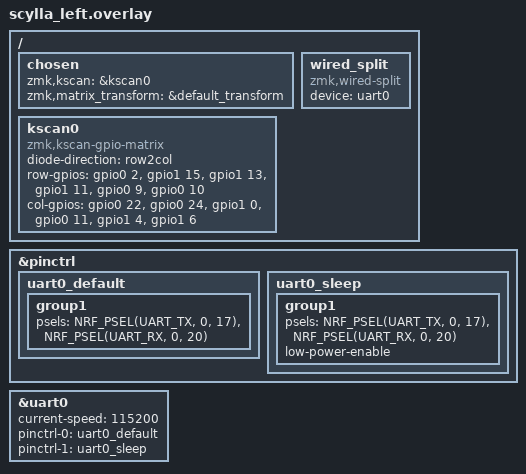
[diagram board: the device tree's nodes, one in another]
#include "scylla.dtsi"

#include <dt-bindings/gpio/gpio.h>
#include <dt-bindings/pinctrl/nrf-pinctrl.h>

/ {
    chosen {
        zmk,kscan = &kscan0;
        zmk,matrix_transform = &default_transform;
    };

    /* Wired split instance (UART) */
    wired_split: wired_split {
        compatible = "zmk,wired-split";
        device = <&uart0>;
    };

    kscan0: kscan0 {
        compatible = "zmk,kscan-gpio-matrix";
        diode-direction = "row2col";

        /* rows */
        row-gpios = <
            &gpio0 2   (GPIO_ACTIVE_HIGH | GPIO_PULL_DOWN)  /* P0.02 */
            &gpio1 15  (GPIO_ACTIVE_HIGH | GPIO_PULL_DOWN)  /* P1.15 */
            &gpio1 13  (GPIO_ACTIVE_HIGH | GPIO_PULL_DOWN)  /* P1.13 */
            &gpio1 11  (GPIO_ACTIVE_HIGH | GPIO_PULL_DOWN)  /* P1.11 */
            &gpio0 9   (GPIO_ACTIVE_HIGH | GPIO_PULL_DOWN)  /* P0.09 thumb row */
            &gpio0 10  (GPIO_ACTIVE_HIGH | GPIO_PULL_DOWN)  /* P0.10 dummy row */
        >;

        /* cols */
        col-gpios = <
            &gpio0 22 (GPIO_ACTIVE_HIGH | GPIO_PULL_DOWN) /* P0.22 */
            &gpio0 24 (GPIO_ACTIVE_HIGH | GPIO_PULL_DOWN) /* P0.24 */
            &gpio1 0  (GPIO_ACTIVE_HIGH | GPIO_PULL_DOWN) /* P1.00 */
            &gpio0 11 (GPIO_ACTIVE_HIGH | GPIO_PULL_DOWN) /* P0.11 */
            &gpio1 4  (GPIO_ACTIVE_HIGH | GPIO_PULL_DOWN) /* P1.04 */
            &gpio1 6  (GPIO_ACTIVE_HIGH | GPIO_PULL_DOWN) /* P1.06 */
        >;
    };
};

/* UART0 pinctrl for nice!nano v2 (Pro Micro header):
 * TX = D1 = P0.17
 * RX = D0 = P0.20
 */
&pinctrl {
    uart0_default: uart0_default {
        group1 {
            psels = <NRF_PSEL(UART_TX, 0, 17)>, <NRF_PSEL(UART_RX, 0, 20)>;
        };
    };

    uart0_sleep: uart0_sleep {
        group1 {
            psels = <NRF_PSEL(UART_TX, 0, 17)>, <NRF_PSEL(UART_RX, 0, 20)>;
            low-power-enable;
        };
    };
};

&uart0 {
    status = "okay";
    current-speed = <115200>;
    pinctrl-0 = <&uart0_default>;
    pinctrl-1 = <&uart0_sleep>;
    pinctrl-names = "default", "sleep";
};
